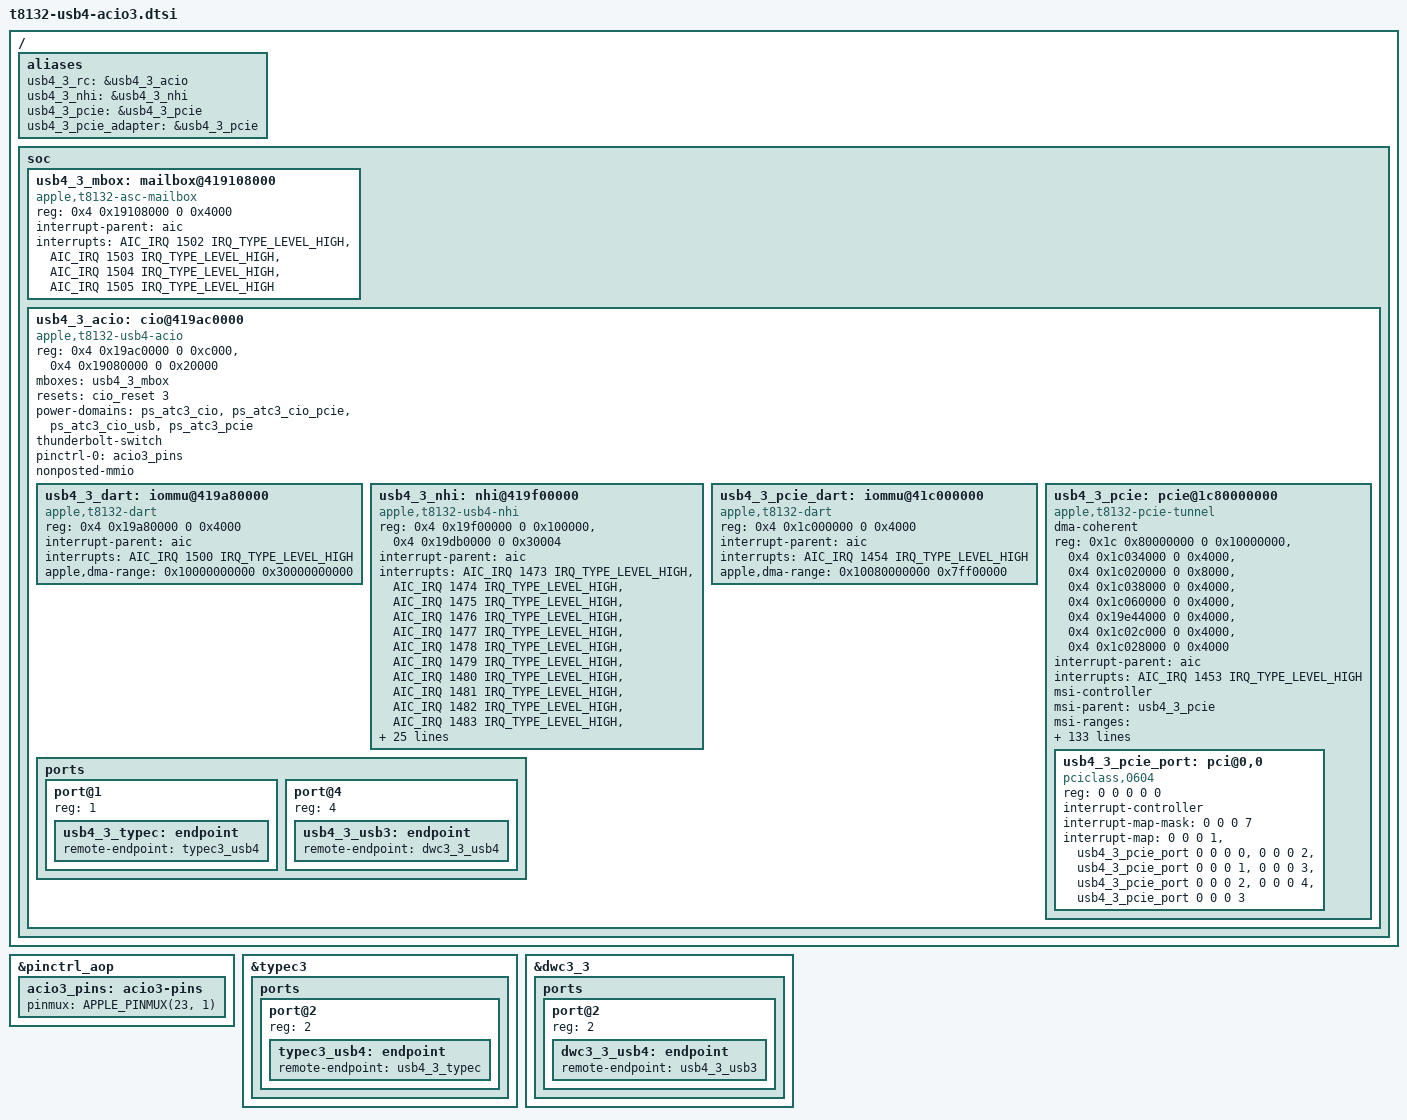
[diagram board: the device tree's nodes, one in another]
// SPDX-License-Identifier: GPL-2.0+ OR MIT
/* T8132 USB4/Thunderbolt on ACIO3 (J773g rear port 3), resources from the J773g ADT. */
/ {
	aliases {
		usb4_3_rc = &usb4_3_acio;
		usb4_3_nhi = &usb4_3_nhi;
		usb4_3_pcie = &usb4_3_pcie;
		usb4_3_pcie_adapter = &usb4_3_pcie;
	};
	soc {
		usb4_3_mbox: mailbox@419108000 {
			compatible = "apple,t8132-asc-mailbox", "apple,asc-mailbox-v4";
			reg = <0x4 0x19108000 0 0x4000>;
			interrupt-parent = <&aic>;
			/* ADT orders each pair as not-empty, empty. */
			interrupts = <AIC_IRQ 1502 IRQ_TYPE_LEVEL_HIGH>,
				     <AIC_IRQ 1503 IRQ_TYPE_LEVEL_HIGH>,
				     <AIC_IRQ 1504 IRQ_TYPE_LEVEL_HIGH>,
				     <AIC_IRQ 1505 IRQ_TYPE_LEVEL_HIGH>;
			interrupt-names = "send-empty",
				"send-not-empty",
				"recv-empty",
				"recv-not-empty";
			#mbox-cells = <0>;
		};
		usb4_3_acio: cio@419ac0000 {
			compatible = "apple,t8132-usb4-acio", "apple,t8103-usb4-acio";
			reg = <0x4 0x19ac0000 0 0xc000>, <0x4 0x19080000 0 0x20000>;
			reg-names = "rc", "sram";
			mboxes = <&usb4_3_mbox>;
			resets = <&cio_reset 3>;
			power-domains = <&ps_atc3_cio>, <&ps_atc3_cio_pcie>,
					<&ps_atc3_cio_usb>, <&ps_atc3_pcie>;
			/* The port controller hands over USB4/TBT mode and cable details. */
			thunderbolt-switch;
			pinctrl-0 = <&acio3_pins>;
			pinctrl-names = "default";
			/* PCIe windows lie outside ACIO's local register aperture. */
			#address-cells = <2>;
			#size-cells = <2>;
			ranges;
			nonposted-mmio;
			usb4_3_dart: iommu@419a80000 {
				compatible = "apple,t8132-dart", "apple,t8110-dart";
				reg = <0x4 0x19a80000 0 0x4000>;
				interrupt-parent = <&aic>;
				interrupts = <AIC_IRQ 1500 IRQ_TYPE_LEVEL_HIGH>;
				#iommu-cells = <1>;
				apple,dma-range = /bits/ 64 <0x10000000000 0x30000000000>;
			};
			usb4_3_nhi: nhi@419f00000 {
				compatible = "apple,t8132-usb4-nhi", "apple,t8103-usb4-nhi";
				reg = <0x4 0x19f00000 0 0x100000>,
				      <0x4 0x19db0000 0 0x30004>;
				reg-names = "nhi", "pdf";
				interrupt-parent = <&aic>;
				interrupts = <AIC_IRQ 1473 IRQ_TYPE_LEVEL_HIGH>,
					<AIC_IRQ 1474 IRQ_TYPE_LEVEL_HIGH>,
					<AIC_IRQ 1475 IRQ_TYPE_LEVEL_HIGH>,
					<AIC_IRQ 1476 IRQ_TYPE_LEVEL_HIGH>,
					<AIC_IRQ 1477 IRQ_TYPE_LEVEL_HIGH>,
					<AIC_IRQ 1478 IRQ_TYPE_LEVEL_HIGH>,
					<AIC_IRQ 1479 IRQ_TYPE_LEVEL_HIGH>,
					<AIC_IRQ 1480 IRQ_TYPE_LEVEL_HIGH>,
					<AIC_IRQ 1481 IRQ_TYPE_LEVEL_HIGH>,
					<AIC_IRQ 1482 IRQ_TYPE_LEVEL_HIGH>,
					<AIC_IRQ 1483 IRQ_TYPE_LEVEL_HIGH>,
					<AIC_IRQ 1484 IRQ_TYPE_LEVEL_HIGH>,
					<AIC_IRQ 1485 IRQ_TYPE_LEVEL_HIGH>,
					<AIC_IRQ 1486 IRQ_TYPE_LEVEL_HIGH>,
					<AIC_IRQ 1487 IRQ_TYPE_LEVEL_HIGH>,
					<AIC_IRQ 1488 IRQ_TYPE_LEVEL_HIGH>,
					<AIC_IRQ 1489 IRQ_TYPE_LEVEL_HIGH>,
					<AIC_IRQ 1490 IRQ_TYPE_LEVEL_HIGH>,
					<AIC_IRQ 1491 IRQ_TYPE_LEVEL_HIGH>,
					<AIC_IRQ 1492 IRQ_TYPE_LEVEL_HIGH>,
					<AIC_IRQ 1493 IRQ_TYPE_LEVEL_HIGH>,
					<AIC_IRQ 1494 IRQ_TYPE_LEVEL_HIGH>,
					<AIC_IRQ 1495 IRQ_TYPE_LEVEL_HIGH>,
					<AIC_IRQ 1496 IRQ_TYPE_LEVEL_HIGH>;
				interrupt-names = "txring0",
					"txring1",
					"txring2",
					"txring3",
					"txring4",
					"txring5",
					"txring6",
					"txring7",
					"txring8",
					"txring9",
					"txring10",
					"txring11",
					"rxring0",
					"rxring1",
					"rxring2",
					"rxring3",
					"rxring4",
					"rxring5",
					"rxring6",
					"rxring7",
					"rxring8",
					"rxring9",
					"rxring10",
					"rxring11";
				/* T8132 has a DART stream for each TX and RX ring. */
				iommus = <&usb4_3_dart 0>,
				<&usb4_3_dart 1>,
				<&usb4_3_dart 2>,
				<&usb4_3_dart 3>,
				<&usb4_3_dart 4>,
				<&usb4_3_dart 5>,
				<&usb4_3_dart 6>,
				<&usb4_3_dart 7>,
				<&usb4_3_dart 8>,
				<&usb4_3_dart 9>,
				<&usb4_3_dart 10>,
				<&usb4_3_dart 11>,
				<&usb4_3_dart 16>,
				<&usb4_3_dart 17>,
				<&usb4_3_dart 18>,
				<&usb4_3_dart 19>,
				<&usb4_3_dart 20>,
				<&usb4_3_dart 21>,
				<&usb4_3_dart 22>,
				<&usb4_3_dart 23>,
				<&usb4_3_dart 24>,
				<&usb4_3_dart 25>,
				<&usb4_3_dart 26>,
				<&usb4_3_dart 27>;
				apple,thunderbolt-drom = [00];
			};
			usb4_3_pcie_dart: iommu@41c000000 {
				compatible = "apple,t8132-dart", "apple,t8110-dart";
				reg = <0x4 0x1c000000 0 0x4000>;
				interrupt-parent = <&aic>;
				interrupts = <AIC_IRQ 1454 IRQ_TYPE_LEVEL_HIGH>;
				#iommu-cells = <1>;
				apple,dma-range = /bits/ 64 <0x10080000000 0x7ff00000>;
			};
			usb4_3_pcie: pcie@1c80000000 {
				compatible = "apple,t8132-pcie-tunnel";
				dma-coherent;
				device_type = "pci";
				reg = <0x1c 0x80000000 0 0x10000000>,
				      <0x4 0x1c034000 0 0x4000>,
				      <0x4 0x1c020000 0 0x8000>,
				      <0x4 0x1c038000 0 0x4000>,
				      <0x4 0x1c060000 0 0x4000>,
				      <0x4 0x19e44000 0 0x4000>,
				      <0x4 0x1c02c000 0 0x4000>,
				      <0x4 0x1c028000 0 0x4000>;
				reg-names = "config",
					"rc",
					"port0",
					"fabric",
					"debug",
					"adapter",
					"ltssm",
					"intr2axi";
				interrupt-parent = <&aic>;
				interrupts = <AIC_IRQ 1453 IRQ_TYPE_LEVEL_HIGH>;
				msi-controller;
				msi-parent = <&usb4_3_pcie>;
				msi-ranges = <&aic AIC_IRQ 1698 IRQ_TYPE_EDGE_RISING 32>;
				apple,msi-vector-base = <192>;
				/*
				 * Give each PCI bus its own DART stream. Keep functions on
				 * the same bus together, as on the other Apple PCIe hosts.
				 * Cover the full bus-range so hotplug bus renumbering does
				 * not alias unrelated buses. PCI ACS and DMA aliases still
				 * determine which streams may use independent domains.
				 */
				iommu-map-mask = <0xff00>;
				iommu-map = <0x0000 &usb4_3_pcie_dart 0 1>,
					    <0x0100 &usb4_3_pcie_dart 1 1>,
					    <0x0200 &usb4_3_pcie_dart 2 1>,
					    <0x0300 &usb4_3_pcie_dart 3 1>,
					    <0x0400 &usb4_3_pcie_dart 4 1>,
					    <0x0500 &usb4_3_pcie_dart 5 1>,
					    <0x0600 &usb4_3_pcie_dart 6 1>,
					    <0x0700 &usb4_3_pcie_dart 7 1>,
					    <0x0800 &usb4_3_pcie_dart 8 1>,
					    <0x0900 &usb4_3_pcie_dart 9 1>,
					    <0x0a00 &usb4_3_pcie_dart 10 1>,
					    <0x0b00 &usb4_3_pcie_dart 11 1>,
					    <0x0c00 &usb4_3_pcie_dart 12 1>,
					    <0x0d00 &usb4_3_pcie_dart 13 1>,
					    <0x0e00 &usb4_3_pcie_dart 14 1>,
					    <0x0f00 &usb4_3_pcie_dart 15 1>,
					    <0x1000 &usb4_3_pcie_dart 16 1>,
					    <0x1100 &usb4_3_pcie_dart 17 1>,
					    <0x1200 &usb4_3_pcie_dart 18 1>,
					    <0x1300 &usb4_3_pcie_dart 19 1>,
					    <0x1400 &usb4_3_pcie_dart 20 1>,
					    <0x1500 &usb4_3_pcie_dart 21 1>,
					    <0x1600 &usb4_3_pcie_dart 22 1>,
					    <0x1700 &usb4_3_pcie_dart 23 1>,
					    <0x1800 &usb4_3_pcie_dart 24 1>,
					    <0x1900 &usb4_3_pcie_dart 25 1>,
					    <0x1a00 &usb4_3_pcie_dart 26 1>,
					    <0x1b00 &usb4_3_pcie_dart 27 1>,
					    <0x1c00 &usb4_3_pcie_dart 28 1>,
					    <0x1d00 &usb4_3_pcie_dart 29 1>,
					    <0x1e00 &usb4_3_pcie_dart 30 1>,
					    <0x1f00 &usb4_3_pcie_dart 31 1>,
					    <0x2000 &usb4_3_pcie_dart 32 1>,
					    <0x2100 &usb4_3_pcie_dart 33 1>,
					    <0x2200 &usb4_3_pcie_dart 34 1>,
					    <0x2300 &usb4_3_pcie_dart 35 1>,
					    <0x2400 &usb4_3_pcie_dart 36 1>,
					    <0x2500 &usb4_3_pcie_dart 37 1>,
					    <0x2600 &usb4_3_pcie_dart 38 1>,
					    <0x2700 &usb4_3_pcie_dart 39 1>,
					    <0x2800 &usb4_3_pcie_dart 40 1>,
					    <0x2900 &usb4_3_pcie_dart 41 1>,
					    <0x2a00 &usb4_3_pcie_dart 42 1>,
					    <0x2b00 &usb4_3_pcie_dart 43 1>,
					    <0x2c00 &usb4_3_pcie_dart 44 1>,
					    <0x2d00 &usb4_3_pcie_dart 45 1>,
					    <0x2e00 &usb4_3_pcie_dart 46 1>,
					    <0x2f00 &usb4_3_pcie_dart 47 1>,
					    <0x3000 &usb4_3_pcie_dart 48 1>,
					    <0x3100 &usb4_3_pcie_dart 49 1>,
					    <0x3200 &usb4_3_pcie_dart 50 1>,
					    <0x3300 &usb4_3_pcie_dart 51 1>,
					    <0x3400 &usb4_3_pcie_dart 52 1>,
					    <0x3500 &usb4_3_pcie_dart 53 1>,
					    <0x3600 &usb4_3_pcie_dart 54 1>,
					    <0x3700 &usb4_3_pcie_dart 55 1>,
					    <0x3800 &usb4_3_pcie_dart 56 1>,
					    <0x3900 &usb4_3_pcie_dart 57 1>,
					    <0x3a00 &usb4_3_pcie_dart 58 1>,
					    <0x3b00 &usb4_3_pcie_dart 59 1>,
					    <0x3c00 &usb4_3_pcie_dart 60 1>,
					    <0x3d00 &usb4_3_pcie_dart 61 1>,
					    <0x3e00 &usb4_3_pcie_dart 62 1>,
					    <0x3f00 &usb4_3_pcie_dart 63 1>,
					    <0x4000 &usb4_3_pcie_dart 64 1>,
					    <0x4100 &usb4_3_pcie_dart 65 1>,
					    <0x4200 &usb4_3_pcie_dart 66 1>,
					    <0x4300 &usb4_3_pcie_dart 67 1>,
					    <0x4400 &usb4_3_pcie_dart 68 1>,
					    <0x4500 &usb4_3_pcie_dart 69 1>,
					    <0x4600 &usb4_3_pcie_dart 70 1>,
					    <0x4700 &usb4_3_pcie_dart 71 1>,
					    <0x4800 &usb4_3_pcie_dart 72 1>,
					    <0x4900 &usb4_3_pcie_dart 73 1>,
					    <0x4a00 &usb4_3_pcie_dart 74 1>,
					    <0x4b00 &usb4_3_pcie_dart 75 1>,
					    <0x4c00 &usb4_3_pcie_dart 76 1>,
					    <0x4d00 &usb4_3_pcie_dart 77 1>,
					    <0x4e00 &usb4_3_pcie_dart 78 1>,
					    <0x4f00 &usb4_3_pcie_dart 79 1>,
					    <0x5000 &usb4_3_pcie_dart 80 1>,
					    <0x5100 &usb4_3_pcie_dart 81 1>,
					    <0x5200 &usb4_3_pcie_dart 82 1>,
					    <0x5300 &usb4_3_pcie_dart 83 1>,
					    <0x5400 &usb4_3_pcie_dart 84 1>,
					    <0x5500 &usb4_3_pcie_dart 85 1>,
					    <0x5600 &usb4_3_pcie_dart 86 1>,
					    <0x5700 &usb4_3_pcie_dart 87 1>,
					    <0x5800 &usb4_3_pcie_dart 88 1>,
					    <0x5900 &usb4_3_pcie_dart 89 1>,
					    <0x5a00 &usb4_3_pcie_dart 90 1>,
					    <0x5b00 &usb4_3_pcie_dart 91 1>,
					    <0x5c00 &usb4_3_pcie_dart 92 1>,
					    <0x5d00 &usb4_3_pcie_dart 93 1>,
					    <0x5e00 &usb4_3_pcie_dart 94 1>,
					    <0x5f00 &usb4_3_pcie_dart 95 1>,
					    <0x6000 &usb4_3_pcie_dart 96 1>,
					    <0x6100 &usb4_3_pcie_dart 97 1>,
					    <0x6200 &usb4_3_pcie_dart 98 1>,
					    <0x6300 &usb4_3_pcie_dart 99 1>,
					    <0x6400 &usb4_3_pcie_dart 100 1>,
					    <0x6500 &usb4_3_pcie_dart 101 1>,
					    <0x6600 &usb4_3_pcie_dart 102 1>,
					    <0x6700 &usb4_3_pcie_dart 103 1>,
					    <0x6800 &usb4_3_pcie_dart 104 1>,
					    <0x6900 &usb4_3_pcie_dart 105 1>,
					    <0x6a00 &usb4_3_pcie_dart 106 1>,
					    <0x6b00 &usb4_3_pcie_dart 107 1>,
					    <0x6c00 &usb4_3_pcie_dart 108 1>,
					    <0x6d00 &usb4_3_pcie_dart 109 1>,
					    <0x6e00 &usb4_3_pcie_dart 110 1>,
					    <0x6f00 &usb4_3_pcie_dart 111 1>,
					    <0x7000 &usb4_3_pcie_dart 112 1>,
					    <0x7100 &usb4_3_pcie_dart 113 1>,
					    <0x7200 &usb4_3_pcie_dart 114 1>,
					    <0x7300 &usb4_3_pcie_dart 115 1>,
					    <0x7400 &usb4_3_pcie_dart 116 1>,
					    <0x7500 &usb4_3_pcie_dart 117 1>,
					    <0x7600 &usb4_3_pcie_dart 118 1>,
					    <0x7700 &usb4_3_pcie_dart 119 1>,
					    <0x7800 &usb4_3_pcie_dart 120 1>,
					    <0x7900 &usb4_3_pcie_dart 121 1>,
					    <0x7a00 &usb4_3_pcie_dart 122 1>,
					    <0x7b00 &usb4_3_pcie_dart 123 1>,
					    <0x7c00 &usb4_3_pcie_dart 124 1>,
					    <0x7d00 &usb4_3_pcie_dart 125 1>,
					    <0x7e00 &usb4_3_pcie_dart 126 1>,
					    <0x7f00 &usb4_3_pcie_dart 127 1>;
				linux,pci-domain = <4>;
				bus-range = <0 127>;
				#address-cells = <3>;
				#size-cells = <2>;
				ranges = <0x43000000 0x14 0 0x14 0 0x2 0>,
					 <0x02000000 0 0x100000 0x16 0x00100000 0 0x3ff00000>;
				usb4_3_pcie_port: pci@0,0 {
					compatible = "pciclass,0604";
					device_type = "pci";
					reg = <0 0 0 0 0>;
					#address-cells = <3>;
					#size-cells = <2>;
					ranges;
					interrupt-controller;
					#interrupt-cells = <1>;
					interrupt-map-mask = <0 0 0 7>;
					interrupt-map = <0 0 0 1 &usb4_3_pcie_port 0 0 0 0>,
							<0 0 0 2 &usb4_3_pcie_port 0 0 0 1>,
							<0 0 0 3 &usb4_3_pcie_port 0 0 0 2>,
							<0 0 0 4 &usb4_3_pcie_port 0 0 0 3>;
				};
			};
			ports {
				#address-cells = <1>;
				#size-cells = <0>;
				port@1 {
					reg = <1>;
					usb4_3_typec: endpoint { remote-endpoint = <&typec3_usb4>; };
				};
				port@4 {
					reg = <4>;
					usb4_3_usb3: endpoint { remote-endpoint = <&dwc3_3_usb4>; };
				};
			};
		};
	};
};
&pinctrl_aop {
	acio3_pins: acio3-pins { pinmux = <APPLE_PINMUX(23, 1)>; };
};
&typec3 {
	ports {
		port@2 {
			reg = <2>;
			typec3_usb4: endpoint { remote-endpoint = <&usb4_3_typec>; };
		};
	};
};
&dwc3_3 {
	ports {
		port@2 {
			reg = <2>;
			dwc3_3_usb4: endpoint { remote-endpoint = <&usb4_3_usb3>; };
		};
	};
};
